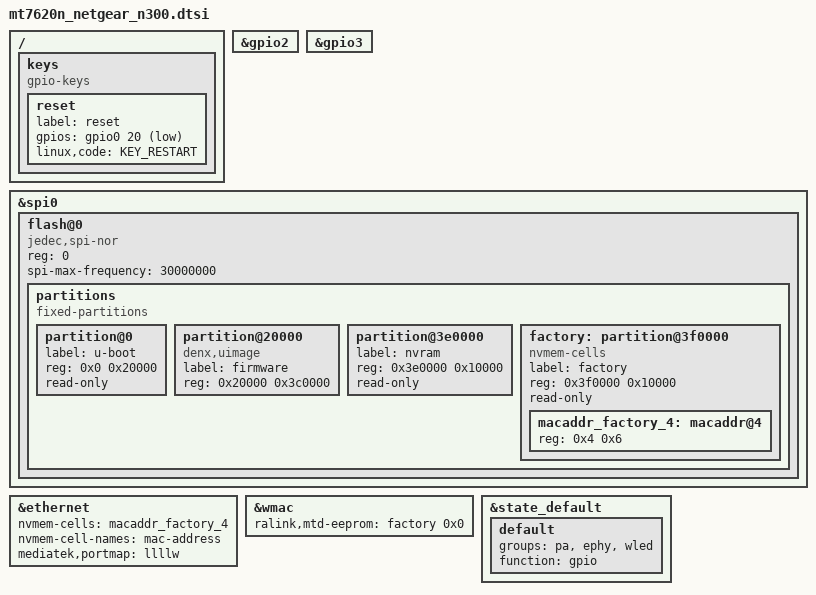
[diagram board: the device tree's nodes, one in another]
// SPDX-License-Identifier: GPL-2.0-or-later OR MIT

#include "mt7620n.dtsi"

#include <dt-bindings/gpio/gpio.h>
#include <dt-bindings/input/input.h>

/ {
	keys {
		compatible = "gpio-keys";

		reset {
			label = "reset";
			gpios = <&gpio0 20 GPIO_ACTIVE_LOW>;
			linux,code = <KEY_RESTART>;
		};
	};
};

&gpio2 {
	status = "okay";
};

&gpio3 {
	status = "okay";
};

&spi0 {
	status = "okay";

	flash@0 {
		compatible = "jedec,spi-nor";
		reg = <0>;
		spi-max-frequency = <30000000>;

		partitions {
			compatible = "fixed-partitions";
			#address-cells = <1>;
			#size-cells = <1>;

			partition@0 {
				label = "u-boot";
				reg = <0x0 0x20000>;
				read-only;
			};

			partition@20000 {
				compatible = "denx,uimage";
				label = "firmware";
				reg = <0x20000 0x3c0000>;
			};

			partition@3e0000 {
				label = "nvram";
				reg = <0x3e0000 0x10000>;
				read-only;
			};

			factory: partition@3f0000 {
				label = "factory";
				reg = <0x3f0000 0x10000>;
				read-only;
			};
		};
	};
};

&ethernet {
	nvmem-cells = <&macaddr_factory_4>;
	nvmem-cell-names = "mac-address";

	mediatek,portmap = "llllw";
};

&wmac {
	ralink,mtd-eeprom = <&factory 0x0>;
};

&state_default {
	default {
		groups = "pa", "ephy", "wled";
		function = "gpio";
	};
};

&factory {
	compatible = "nvmem-cells";
	#address-cells = <1>;
	#size-cells = <1>;

	macaddr_factory_4: macaddr@4 {
		reg = <0x4 0x6>;
	};
};
